# RE01_256KB register map
Vendor: Renesas Electronics Corporation; Series: RE01; File version: 1.00.01
CPU: CM0PLUS r0p1, little endian, MPU, no FPU, VTOR, 2 interrupt priority bits, 32 interrupts
Registers are 8-bit, read-write, reset 0x0 unless marked. A register's access mark holds for its fields unless they carry their own. Offsets are from the block's base; [hi:lo] are bit positions; lines under a group give offsets from that group; {n}, {i} and the like mark numbered series; 'fields as' and 'values as' point back to an identical list; <NAME> marks a mode.

## ADC140 — 14-bit A/D Converter
Base 0x4005C000
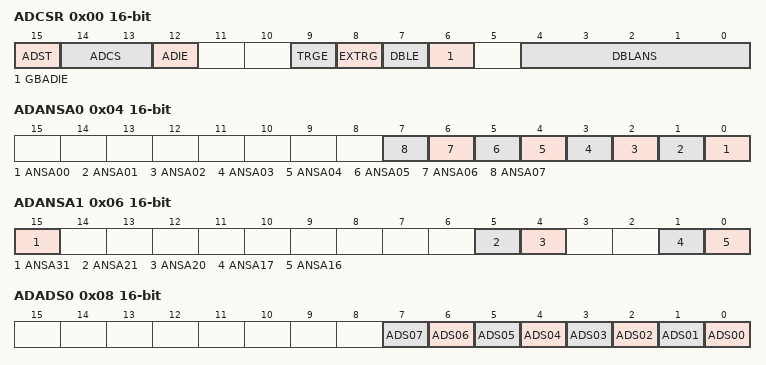
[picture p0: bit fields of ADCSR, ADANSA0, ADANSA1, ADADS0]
0x00 ADCSR 16-bit — A/D Control Register
  [15] ADST — A/D Conversion Start
    0=Stop A/D conversion process; 1=Start A/D conversion process
  [14:13] ADCS — Scan Mode Select
    0=Single scan mode; 1=Group scan mode; 2=Continuous scan mode; 3=Setting prohibited
  [12] ADIE
    0=Disable ADC140_ADIADC140_ADI interrupt generation upon completion of scanning; 1=Enable ADC140_ADI interrupt generation upon completion of scanning
  [9] TRGE — Trigger Start Enable
    0=Disable A/D conversion to be started by the synchronous or asynchronous trigger; 1=Enable A/D conversion to be started by the synchronous or asynchronous trigger
  [8] EXTRG — Trigger Select
    0=Start A/D conversion by the synchronous trigger (TMR, ELC); 1=Start A/D conversion by the asynchronous trigger (ADTRG0)
  [7] DBLE — Double Trigger Mode Select
    0=Deselect double-trigger mode; 1=Select double-trigger mode
  [6] GBADIE — Group B Scan End Interrupt and ELC Event Enable
    0=Disable ADC140_GBADI interrupt generation on group B scan completion; 1=Enable ADC140_GBADI interrupt generation on group B scan completion
  [4:0] DBLANS — Double Trigger Channel Select
0x04 ADANSA0 16-bit — A/D Channel Select Register A0
  [all] fields
    0=Do not select associated input channel; 1=Select associated input channel
  [n] ANSA{n:02} (n=0..7) — A/D Conversion Channels Select
0x06 ADANSA1 16-bit — A/D Channel Select Register A1
  [all] fields
    values as the fields of ADANSA0
  [15] ANSA31 — A/D Conversion Channels Select
  [5] ANSA21 — A/D Conversion Channels Select
  [4] ANSA20 — A/D Conversion Channels Select
  [1] ANSA17 — A/D Conversion Channels Select
  [0] ANSA16 — A/D Conversion Channels Select
0x08 ADADS0 16-bit — A/D-Converted Value Addition/Average Channel Select Register 0
  [all] fields
    values as the fields of ADANSA0
  [n] ADS{n:02} (n=0..7) — A/D-Converted Value Addition/Average Channel Select
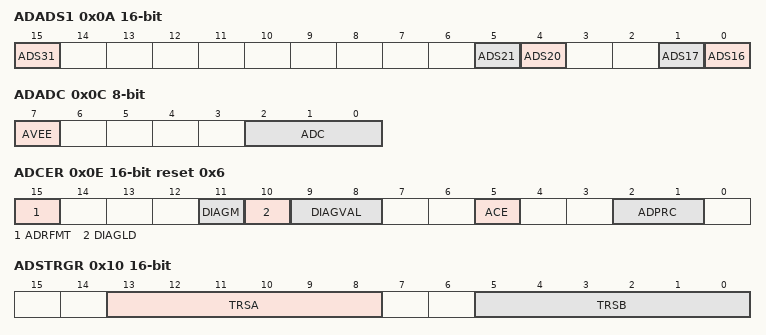
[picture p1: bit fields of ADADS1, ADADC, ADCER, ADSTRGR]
0x0A ADADS1 16-bit — A/D-Converted Value Addition/Average Channel Select Register 1
  [all] fields
    values as the fields of ADANSA0
  [15] ADS31 — A/D-Converted Value Addition/Average Channel Select
  [5] ADS21 — A/D-Converted Value Addition/Average Channel Select
  [4] ADS20 — A/D-Converted Value Addition/Average Channel Select
  [1] ADS17 — A/D-Converted Value Addition/Average Channel Select
  [0] ADS16 — A/D-Converted Value Addition/Average Channel Select
0x0C ADADC — A/D-Converted Value Addition/Average Count Select Register
  [7] AVEE — Average Mode Select
    0=Enable addition mode; 1=Enable average mode
  [2:0] ADC — Addition/Average Count Select
    0=1-time conversion (no addition, same as normal conversion); 1=2-time conversion (one addition); 2=Setting prohibited; 3=4-time conversion (three additions); 5=16-time conversion (15 additions); other=Others (Setting prohibited)
0x0E ADCER 16-bit reset 0x6 — A/D Control Extended Register
  [15] ADRFMT — A/D Data Register Format Select
    0=Select right-justified for the A/D data register format; 1=Select left-justified for the A/D data register format
  [11] DIAGM — Self-Diagnosis Enable
    0=Disable ADC14 self-diagnosis; 1=Enable ADC14 self-diagnosis
  [10] DIAGLD — Self-Diagnosis Mode Select
    0=Select rotation mode for self-diagnosis voltage; 1=Select mixed mode for self-diagnosis voltage
  [9:8] DIAGVAL — Self-Diagnosis Conversion Voltage Select
    0=Setting prohibited when self-diagnosis is enabled; 1=0 volts; 2=Reference power supply voltage × 1/2; 3=Reference power supply voltage
  [5] ACE — A/D Data Register Automatic Clearing Enable
    0=Disable automatic clearing; 1=Enable automatic clearing
  [2:1] ADPRC
    0=12-bit accuracy; 1=Setting prohibited; 2=Setting prohibited; 3=14-bit accuracy
0x10 ADSTRGR 16-bit — A/D Conversion Start Trigger Select Register
  [13:8] TRSA — A/D Conversion Start Trigger Select
  [5:0] TRSB — A/D Conversion Start Trigger Select for Group B
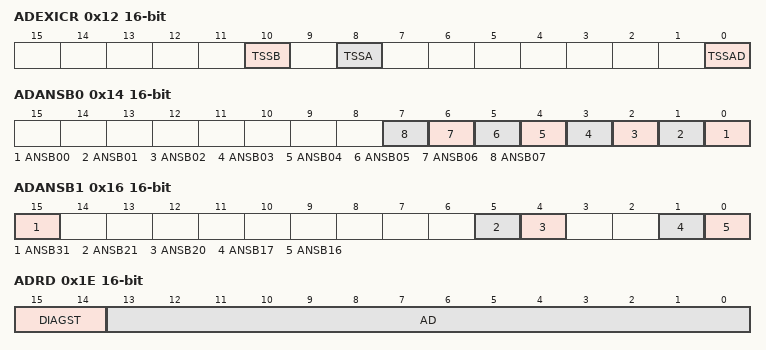
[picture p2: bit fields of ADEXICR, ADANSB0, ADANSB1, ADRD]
0x12 ADEXICR 16-bit — A/D Conversion Extended Input Control Registers
  [10] TSSB — Temperature Sensor Output A/D Conversion Select for Group B
    0=Disable A/D conversion of temperature sensor output; 1=Enable A/D conversion of temperature sensor output
  [8] TSSA — Temperature Sensor Output A/D Conversion Select
    values as TSSB
  [0] TSSAD — Temperature Sensor Output A/D-Converted Value Addition/Average Mode Select
    0=Do not select addition/average mode for temperature sensor output; 1=Select addition/average mode for temperature sensor output
0x14 ADANSB0 16-bit — A/D Channel Select Register B0
  [all] fields
    values as the fields of ADANSA0
  [n] ANSB{n:02} (n=0..7) — A/D Conversion Channels Select
0x16 ADANSB1 16-bit — A/D Channel Select Register B1
  [all] fields
    values as the fields of ADANSA0
  [15] ANSB31 — A/D Conversion Channels Select
  [5] ANSB21 — A/D Conversion Channels Select
  [4] ANSB20 — A/D Conversion Channels Select
  [1] ANSB17 — A/D Conversion Channels Select
  [0] ANSB16 — A/D Conversion Channels Select
0x18 ADDBLDR 16-bit ro — A/D Data Duplexing Register
  [15:0] ADDBLDR — Converted Value 15 to 0
0x1A ADTSDR 16-bit ro — A/D Temperature Sensor Data Register
  [15:0] ADTSDR — Converted Value 15 to 0
0x1E ADRD 16-bit ro — A/D Self-Diagnosis Data Register
  [15:14] DIAGST — Self-Diagnosis Status
    0=Self-diagnosis not executed after power-on; 1=Self-diagnosis was executed using the 0 V voltage; 2=Self-diagnosis was executed using the reference power supply voltage x 1/2; 3=Self-diagnosis was executed using the reference power supply voltage
  [13:0] AD — Converted Value 13 to 0
{0x20+2i} ADDR{i} (i=0..7) 16-bit ro — A/D Data Registers {i}
  [15:0] ADDRn — Converted Value 15 to 0
{0x20+2i} ADDR{i} (i=16..17) 16-bit ro — A/D Data Registers {i}
  [15:0] ADDRn — Converted Value 15 to 0
{0x20+2i} ADDR{i} (i=20..21) 16-bit ro — A/D Data Registers {i}
  [15:0] ADDRn — Converted Value 15 to 0
0x5E ADVSCDR 16-bit ro — A/D VSC_VCC Voltage Voltage Data Register
  [15:0] ADVSCDR — Converted Value 15 to 0
0x64 ADSCLKCR — A/D Sub-Clock Mode Control Register
  [0] SCLKEN — Sub-Clock Mode Setting
    0=When the ADCLK frequency is set to 1 to 32 MHz; 1=When the ADCLK frequency is set to 32.768 kHz
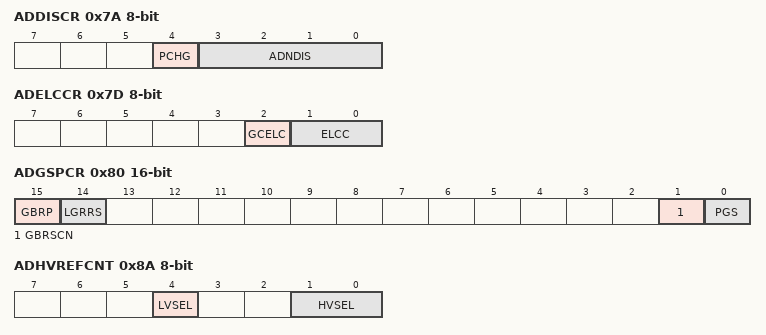
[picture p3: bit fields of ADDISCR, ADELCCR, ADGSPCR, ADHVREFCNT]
0x7A ADDISCR — A/D Disconnection Detection Control Register
  [4] PCHG — Precharge/discharge select
    0=Discharge; 1=Precharge
  [3:0] ADNDIS — Disconnection Detection Assist Setting
    0=The disconnection detection assist function is disabled; 1=Setting prohibited; other=Others (The number of states for the discharge or precharge period.)
0x7D ADELCCR — A/D Event Link Control Register
  [2] GCELC — Group C Event Link Control
    0=No event is generated when group C scan completes in groupscan mode; 1=An event is generated when group C scan completes in groupscan mode
  [1:0] ELCC — Event Link Control
    0=An event is generated upon completion of scanning other than group B and group C scans in group-scan mode; 1=An event is generated when group B scan completes in group-scan mode; 0b1x=An event is generated when all scans complete
0x80 ADGSPCR 16-bit — A/D Group Scan Priority Control Register
  [15] GBRP — Single Scan Continuous Start
    0=Single scan is not continuously activated; 1=Single scan for the group with the lowest-priority is continuously activated
  [14] LGRRS — Enabled only when PGS = 1 and GBRSCN = 1.
    0=Start rescanning from the first channel for scanning; 1=Start rescanning from the channel for which A/D conversion is not completed
  [1] GBRSCN — Lower-Priority Group Restart Setting
    0=Disable rescanning of the group that was stopped in group priority operation; 1=Enable rescanning of the group that was stopped in group priority operation
  [0] PGS — Group Priority Operation Setting
    0=Operate without group priority control; 1=Operate with group priority control
0x8A ADHVREFCNT — A/D High-Potential/Low-Potential Reference Voltage Control Register
  [4] LVSEL — Low-Potential Reference Voltage Select
    0=AVSS0 is selected as the low-potential reference voltage; 1=VREFL0 is selected as the low-potential reference voltage
  [1:0] HVSEL — High-Potential Reference Voltage Select
    0=AVCC0 is selected as the high-potential reference voltage; 1=VREFH0 is selected as the high-potential reference voltage; 2=No reference voltage pin is selected; 3=No reference voltage pin is selected (internal node discharge)
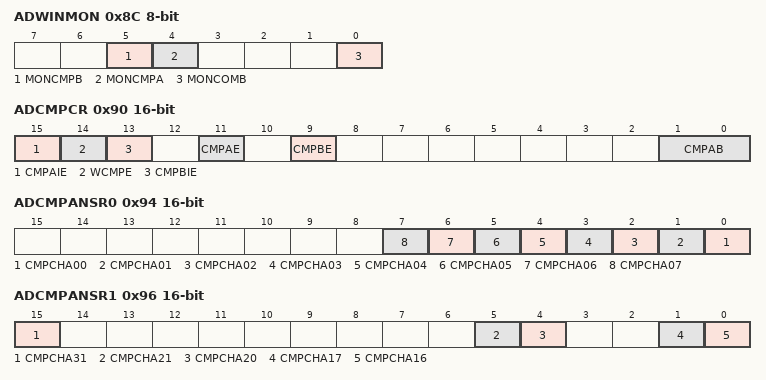
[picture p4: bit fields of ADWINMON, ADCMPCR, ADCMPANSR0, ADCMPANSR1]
0x8C ADWINMON ro — A/D Compare Function Window A/B Status Monitor Register
  [5] MONCMPB — Comparison Result Monitor B
    0=Window B comparison conditions are not met; 1=Window B comparison conditions are met
  [4] MONCMPA — Comparison Result Monitor A
    0=Window A comparison conditions are not met; 1=Window A comparison conditions are met
  [0] MONCOMB — Combination Result Monitor
    0=Window A/B composite conditions are not met; 1=Window A/B composite conditions are met
0x90 ADCMPCR 16-bit — A/D Compare Function Control Register
  [15] CMPAIE — Compare A Interrupt Enable
    0=Disable ADC140_CMPAI interrupt when comparison conditions (window A) are met; 1=Enable ADC140_CMPAI interrupt when comparison conditions (window A) are met
  [14] WCMPE — Window Function Setting
    0=Disable window function Window A and window B operate as a comparator to compare the single value on the lower side with the A/D conversion result; 1=Enable window function Window A and window B operate as a comparator to compare the two values on the upper and lower sides with the A/D conversion result
  [13] CMPBIE — Compare B Interrupt Enable
    0=Disable ADC140_CMPBI interrupt when comparison conditions (window B) are met; 1=Enable ADC140_CMPBI interrupt when comparison conditions (window B) are met
  [11] CMPAE — Compare Window A Operation Enable
    0=Disable compare window A operation. Disable ADC140_WCMPM and ADC140_WCMPUM outputs.; 1=Enable compare window A operation
  [9] CMPBE — Compare Window B Operation Enable
    0=Disable compare window B operation. Disable ADC140_WCMPM and ADC140_WCMPUM outputs.; 1=Enable compare window B operation
  [1:0] CMPAB — Window A/B Composite Conditions Setting
    0=Output ADC140_WCMPM when window A OR window B comparison conditions are met. Otherwise, output ADC140_WCMPUM.; 1=Output ADC140_WCMPM when window A EXOR window B comparison conditions are met. Otherwise, output ADC140_WCMPUM.; 2=Output ADC140_WCMPM when window A AND window B comparison conditions are met. Otherwise, output ADC140_WCMPUM.; 3=Setting prohibited
0x92 ADCMPANSER — A/D Compare Function Window A Extended Input Select Register
  [0] CMPTSA — Temperature Sensor Output Compare Select
    0=Exclude the temperature sensor output from the compare Window A target range; 1=Include the temperature sensor output in the compare Window A target range
0x93 ADCMPLER — A/D Compare Function Window A Extended Input Comparison Condition Setting Register
  [0] CMPLTSA — Compare Window A Temperature Sensor Output Comparison Condition Select
    0=When window function is disabled (ADCMPCR.WCMPE = 0) : ADCMPDR0 value > A/D-converted valueCompare Window A Temperature Sensor Output Comparison Condition Select When window function is enabled (ADCMPCR.WCMPE = 1) : Compare Window A Temperature Sensor Output Comparison ConditionA/D-converted value < ADCMPDR0 value, or A/D-converted value > ADCMPDR1 value; 1=When window function is disabled (ADCMPCR.WCMPE = 0) : ADCMPDR0 value < A/D-converted value When window function is enabled (ADCMPCR.WCMPE = 1) : ADCMPDR0 value < A/D-converted value < ADCMPDR1 value
0x94 ADCMPANSR0 16-bit — A/D Compare Function Window A Channel Select Register 0
  [all] fields
    0=Disable compare function for associated input channel; 1=Enable compare function for associated input channel
  [n] CMPCHA{n:02} (n=0..7) — Compare Window A Channel Select
0x96 ADCMPANSR1 16-bit — A/D Compare Function Window A Channel Select Register 1
  [all] fields
    values as the fields of ADCMPANSR0
  [15] CMPCHA31 — Compare Window A Channel Select
  [5] CMPCHA21 — Compare Window A Channel Select
  [4] CMPCHA20 — Compare Window A Channel Select
  [1] CMPCHA17 — Compare Window A Channel Select
  [0] CMPCHA16 — Compare Window A Channel Select
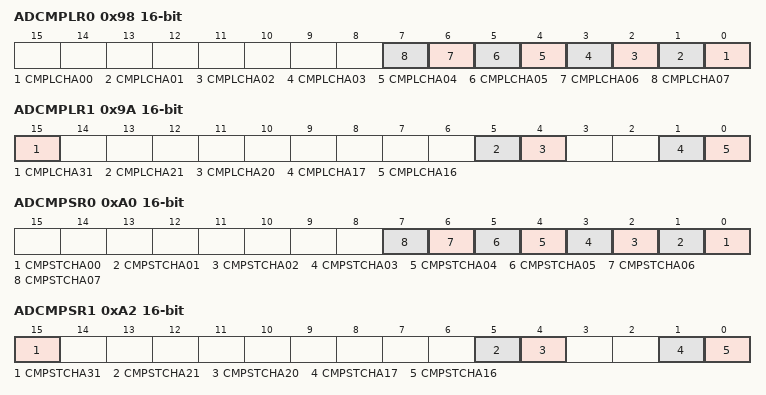
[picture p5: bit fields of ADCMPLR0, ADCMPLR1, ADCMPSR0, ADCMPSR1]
0x98 ADCMPLR0 16-bit — A/D Compare Function Window A Comparison Condition Setting Register 0
  [all] fields
    0=When window function is disabled (ADCMPCR.WCMPE = 0): ADCMPDR0 value > A/D-converted value When window function is enabled (ADCMPCR.WCMPE = 1): A/D-converted value < ADCMPDR0 value, or ADCMPDR1 value < A/D-converted value; 1=When window function is disabled (ADCMPCR.WCMPE = 0): ADCMPDR0 value < A/D-converted value When window function is enabled (ADCMPCR.WCMPE = 1): ADCMPDR0 value < A/D-converted value < ADCMPDR1 value
  [n] CMPLCHA{n:02} (n=0..7) — Compare Window A Comparison Condition Select
0x9A ADCMPLR1 16-bit — A/D Compare Function Window A Comparison Condition Setting Register 1
  [all] fields
    values as the fields of ADCMPLR0
  [15] CMPLCHA31 — Compare Window A Comparison Condition Select
  [5] CMPLCHA21 — Compare Window A Comparison Condition Select
  [4] CMPLCHA20 — Compare Window A Comparison Condition Select
  [1] CMPLCHA17 — Compare Window A Comparison Condition Select
  [0] CMPLCHA16 — Compare Window A Comparison Condition Select
{0x9C+2i} ADCMPDR{i} (i=0..1) 16-bit — A/D Compare Function Window A Lower-Side/Upper-Side Level Setting Register
0xA0 ADCMPSR0 16-bit — A/D Compare Function Window A Channel Status Register 0
  [all] fields
    0=Comparison conditions are not met; 1=Comparison conditions are met
  [n] CMPSTCHA{n:02} (n=0..7) — Compare Window A Flag
0xA2 ADCMPSR1 16-bit — A/D Compare Function Window A Channel Status Register1
  [all] fields
    values as the fields of ADCMPSR0
  [15] CMPSTCHA31 — Compare Window A Flag
  [5] CMPSTCHA21 — Compare Window A Flag
  [4] CMPSTCHA20 — Compare Window A Flag
  [1] CMPSTCHA17 — Compare Window A Flag
  [0] CMPSTCHA16 — Compare Window A Flag
0xA4 ADCMPSER — A/D Compare Function Window A Extended Input Channel Status Register
  [0] CMPSTTSA — Compare Window A Temperature Sensor Output Compare Flag
    values as the fields of ADCMPSR0
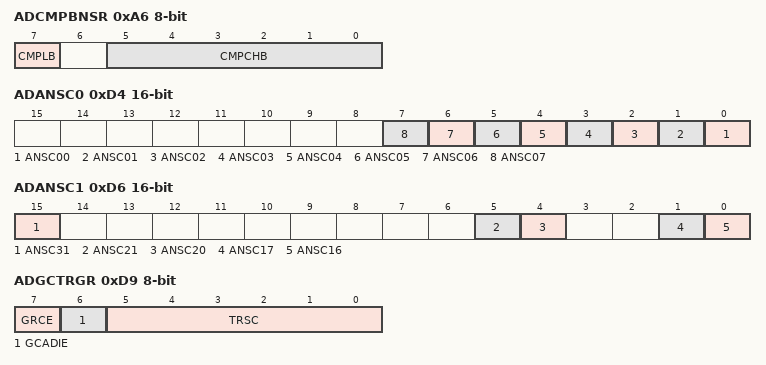
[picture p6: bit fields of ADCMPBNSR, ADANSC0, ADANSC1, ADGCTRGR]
0xA6 ADCMPBNSR — A/D Compare Function Window B Channel Select Register
  [7] CMPLB — Compare Window B Comparison Condition Setting
    0=When window function is disabled (ADCMPCR.WCMPE = 0): ADWINLLB value > A/D-converted value When window function is enabled (ADCMPCR.WCMPE = 1): A/D-converted value < ADWINLLB value, or ADWINULB value < A/D-converted value; 1=When window function is disabled (ADCMPCR.WCMPE = 0): ADWINLLB value < A/D-converted value When window function is enabled (ADCMPCR.WCMPE = 1): ADWINLLB value < A/D-converted value < ADWINULB value
  [5:0] CMPCHB — Compare Window B Channel Select
0xA8 ADWINLLB 16-bit — A/D Compare Function Window B Lower-Side/Upper-Side Level Setting Register
0xAA ADWINULB 16-bit — A/D Compare Function Window B Lower-Side/Upper-Side Level Setting Register
0xAC ADCMPBSR — A/D Compare Function Window B Status Register
  [0] CMPSTB — Compare Window B Flag
    values as the fields of ADCMPSR0
0xD4 ADANSC0 16-bit — A/D Channel Select Register C0
  [all] fields
    0=The associated input channel is not selected; 1=The associated input channel is selected
  [n] ANSC{n:02} (n=0..7) — A/D Conversion Channels Select
0xD6 ADANSC1 16-bit — A/D Channel Select Register C1
  [all] fields
    values as the fields of ADANSC0
  [15] ANSC31 — A/D Conversion Channels Select
  [5] ANSC21 — A/D Conversion Channels Select
  [4] ANSC20 — A/D Conversion Channels Select
  [1] ANSC17 — A/D Conversion Channels Select
  [0] ANSC16 — A/D Conversion Channels Select
0xD8 ADGCEXCR — A/D Group C Extended Input Control Register
  [0] TSSC — Temperature Sensor Output A/D Conversion Select for Group C
    values as ADEXICR.TSSB
0xD9 ADGCTRGR — A/D Group C Trigger Select Register
  [7] GRCE — A/D Conversion Operation Enable for Group C
    0=Do no use group C; 1=Use group C
  [6] GCADIE — Group C Scan End Interrupt Enable
    0=Disable ADC140_GCADI interrupt generation upon completion of group C scan; 1=Enable ADC140_GCADI interrupt generation upon completion of group C scan
  [5:0] TRSC — A/D Conversion Start Trigger Select for Group C
0xDD ADSSTRL reset 0xF — A/D Sampling State Register
  [7:0] SST — Sampling Time Setting
0xDE ADSSTRT reset 0xF — A/D Sampling State Register
  [7:0] SST — Sampling Time Setting
{0xE0+i} ADSSTR{i} (i=0..7) reset 0xF — A/D Sampling State Register
  [7:0] SST — Sampling Time Setting
0x140 ADCALC reset 0x40 — A/D Calibration Control Register
  [7] CALST — Offset Calibration
    0=Disable offset calibration when A/D conversion starts the next time; 1=Enable offset calibration when A/D conversion starts the next time
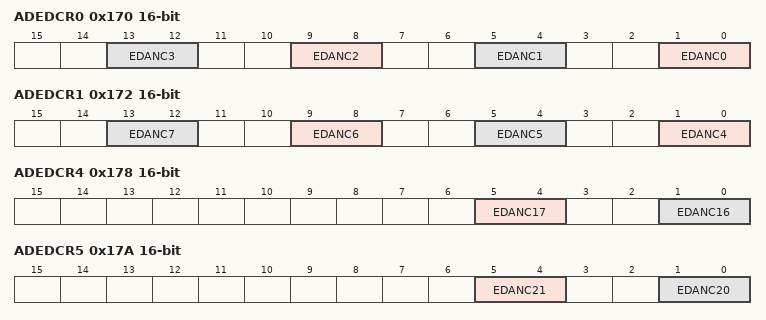
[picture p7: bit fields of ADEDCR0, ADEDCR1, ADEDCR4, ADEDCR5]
0x170 ADEDCR0 16-bit — A/D Emulator Debug Function Control Register 0
  [all] fields
    0=Disable the emulator debug function; 1=Replace the value of the ADEDDMY0.EDDMY0 dummy data register with the A/D conversion result; 2=Replace the value of the ADEDDMY1.EDDMY1 dummy data register with the A/D conversion result; 3=Setting prohibited
  [4n+1:4n] EDANC{n} (n=0..3) — Emulator Debug Function Control
0x172 ADEDCR1 16-bit — A/D Emulator Debug Function Control Register 1
  [all] fields
    values as the fields of ADEDCR0
  [4n-15:4n-16] EDANC{n} (n=4..7) — Emulator Debug Function Control
0x178 ADEDCR4 16-bit — A/D Emulator Debug Function Control Register 4
  [5:4] EDANC17 — Emulator Debug Function Control
    values as the fields of ADEDCR0
  [1:0] EDANC16 — Emulator Debug Function Control
    values as the fields of ADEDCR0
0x17A ADEDCR5 16-bit — A/D Emulator Debug Function Control Register 5
  [5:4] EDANC21 — Emulator Debug Function Control
    values as the fields of ADEDCR0
  [1:0] EDANC20 — Emulator Debug Function Control
    values as the fields of ADEDCR0
0x17E ADEDCR7 16-bit — A/D Emulator Debug Function Control Register 7
  [13:12] EDANC31 — Emulator Debug Function Control
    values as the fields of ADEDCR0
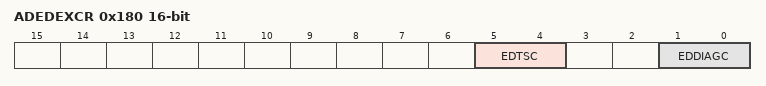
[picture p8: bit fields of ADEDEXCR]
0x180 ADEDEXCR 16-bit — A/D Emulator Debug Function Extension Control Register
  [5:4] EDTSC — Emulator Debug Function Temperature Sensor Output Control
    0=Disable the emulator debug function; 1=Replace the EDDMY0 value of the Dummy Data Register (ADEDDMY0) with the A/D conversion result; 2=Replace the EDDMY1 value of the Dummy Data Register (ADEDDMY1) with the A/D conversion result; 3=Setting prohibited
  [1:0] EDDIAGC — Emulator Debug Function Self-Diagnosis Control
    values as EDTSC
0x182 ADEDDMY0 16-bit — A/D Emulator Debug Function Dummy Data Setting Register 0
  [13:0] EDDMY0 — Dummy Data Setting 0
0x184 ADEDDMY1 16-bit — A/D Emulator Debug Function Dummy Data Setting Register 1
  [13:0] EDDMY1 — Dummy Data Setting 1
0x1C0 ADSCS0 — A/D Channel Conversion Order Setting Register 0
  [4:0] SCS00 — (mth) Conversion Channel Setting
0x1C1 ADSCS1 reset 0x1 — A/D Channel Conversion Order Setting Register 1
  [4:0] SCS01 — (mth) Conversion Channel Setting
0x1C2 ADSCS2 reset 0x2 — A/D Channel Conversion Order Setting Register 2
  [4:0] SCS02 — (mth) Conversion Channel Setting
0x1C3 ADSCS3 reset 0x3 — A/D Channel Conversion Order Setting Register 3
  [4:0] SCS03 — (mth) Conversion Channel Setting
0x1C4 ADSCS4 reset 0x4 — A/D Channel Conversion Order Setting Register 4
  [4:0] SCS04 — (mth) Conversion Channel Setting
0x1C5 ADSCS5 reset 0x5 — A/D Channel Conversion Order Setting Register 5
  [4:0] SCS05 — (mth) Conversion Channel Setting
0x1C6 ADSCS6 reset 0x6 — A/D Channel Conversion Order Setting Register 6
  [4:0] SCS06 — (mth) Conversion Channel Setting
0x1C7 ADSCS7 reset 0x7 — A/D Channel Conversion Order Setting Register 7
  [4:0] SCS07 — (mth) Conversion Channel Setting
0x1D0 ADSCS16 reset 0x10 — A/D Channel Conversion Order Setting Register 16
  [4:0] SCS16 — (mth) Conversion Channel Setting
0x1D1 ADSCS17 reset 0x11 — A/D Channel Conversion Order Setting Register 17
  [4:0] SCS17 — (mth) Conversion Channel Setting
0x1D4 ADSCS20 reset 0x14 — A/D Channel Conversion Order Setting Register 20
  [4:0] SCS20 — (mth) Conversion Channel Setting
0x1D5 ADSCS21 reset 0x15 — A/D Channel Conversion Order Setting Register 21
  [4:0] SCS21 — (mth) Conversion Channel Setting
0x1DF ADSCS31 reset 0x1F — A/D Channel Conversion Order Setting Register 31
  [4:0] SCS31 — (mth) Conversion Channel Setting
